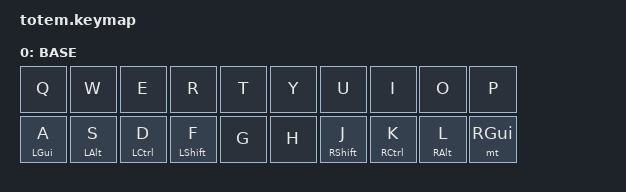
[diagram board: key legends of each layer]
//
//                                                        ▀▀▀▀▀     ▀▀▀▀▀          ▀▀█▀▀
//                                                        ▄▀▀▀▄  ▄  ▄▀▀▀▄  ▄  ▄▀▀▀▄  █  ▄▀▀▀▄
//                                                        █   █  █  █   █  █  █   █  █  █   █
//                                                         ▀▀▀   █   ▀▀▀   █   ▀▀▀   ▀   ▀▀▀
//                                                               █      ▄▄▄█▄▄▄    █   █  
//                                                               ▀      █  █  █     █▄█
//                                                             ▀▀▀▀▀    █  █  █      ▀
//                                                                      ▀  ▀  ▀
//
// ▄▄▄▄▄▄▄▄▄▄▄▄▄▄▄▄▄▄▄▄▄▄▄▄▄▄▄▄▄▄▄▄▄▄▄▄▄▄▄▄▄▄▄▄▄▄▄▄▄▄▄▄▄▄▄▄▄▄▄▄▄▄▄▄▄▄▄▄▄▄▄▄▄▄▄▄▄▄▄▄▄▄▄▄▄▄▄▄▄▄▄▄▄▄▄▄▄▄▄▄▄▄▄▄▄▄▄▄▄▄▄▄▄▄▄▄▄▄▄▄▄▄▄▄▄▄▄▄▄▄▄▄▄▄▄▄▄▄▄▄▄▄▄▄▄▄▄▄▄
       

#include <behaviors.dtsi>
#include <dt-bindings/zmk/keys.h>
#include <dt-bindings/zmk/bt.h>
#include <dt-bindings/zmk/outputs.h>

#define BASE 0

&mt {
  quick-tap-ms = <100>;
  global-quick-tap;
  flavor = "tap-preferred";
  tapping-term-ms = <170>;
};

/ {
     combos {
            compatible = "zmk,combos";
            combo_esc {
                timeout-ms = <50>;
                key-positions = <0 1>;
                bindings = <&kp ESC>;
            };
            combo_tvp {
                timeout-ms = <100>;
                key-positions = <11 12 13>;
                bindings = <&tog TVP1>;
            };
    };

    macros {
        gif: gif {
            label = "giphy";
            compatible = "zmk,behavior-macro";
            #binding-cells = <0>;
            bindings
                = <&macro_press &kp LSHFT>
                , <&macro_tap &kp N2>
                , <&macro_release &kp LSHFT>
                , <&macro_tap &kp G &kp I &kp F>
                ;
        };
    };

        keymap {
                compatible = "zmk,keymap";
// ▄▄▄▄▄▄▄▄▄▄▄▄▄▄▄▄▄▄▄▄▄▄▄▄▄▄▄▄▄▄▄▄▄▄▄▄▄▄▄▄▄▄▄▄▄▄▄▄▄▄▄▄▄▄▄▄▄▄▄▄▄▄▄▄▄▄▄▄▄▄▄▄▄▄▄▄▄▄▄▄▄▄▄▄▄▄▄▄▄▄▄▄▄▄▄▄▄▄▄▄▄▄▄▄▄▄▄▄▄▄▄▄▄▄▄▄▄▄▄▄▄▄▄▄▄▄▄▄▄▄▄▄▄▄▄▄▄▄▄▄▄▄▄▄▄▄▄▄▄

                base_layer {
// ┏━━━━━━━━━━━━━━━━━━━━━━━━━━━━━━━━━━━━━━━┓
label= "BASE"                              ;
// ┗━━━━━━━━━━━━━━━━━━━━━━━━━━━━━━━━━━━━━━━┛
//             ┏━━━━━━━━━━━┳━━━━━━━━━━━┳━━━━━━━━━━━┳━━━━━━━━━━━┳━━━━━━━━━━━┓   ┏━━━━━━━━━━━┳━━━━━━━━━━━┳━━━━━━━━━━━┳━━━━━━━━━━━┳━━━━━━━━━━━┓
//             ┃     Q     ┃     W     ┃     E     ┃     R     ┃     T     ┃   ┃     Y     ┃     U     ┃     I     ┃     O     ┃     P     ┃
//             ┣━━━━━━━━━━━╋━━━━━━━━━━━╋━━━━━━━━━━━╋━━━━━━━━━━━╋━━━━━━━━━━━┫   ┣━━━━━━━━━━━╋━━━━━━━━━━━╋━━━━━━━━━━━╋━━━━━━━━━━━╋━━━━━━━━━━━┫
//             ┃     A     ┃     S     ┃     D     ┃     F     ┃     G     ┃   ┃     H     ┃     J     ┃     K     ┃     L     ┃     ;     ┃
// ┏━━━━━━━━━━━╋━━━━━━━━━━━╋━━━━━━━━━━━╋━━━━━━━━━━━╋━━━━━━━━━━━╋━━━━━━━━━━━┫   ┣━━━━━━━━━━━╋━━━━━━━━━━━╋━━━━━━━━━━━╋━━━━━━━━━━━╋━━━━━━━━━━━╋━━━━━━━━━━━┓
// ┃    HYP    ┃     Z     ┃     X     ┃     C     ┃     V     ┃     B     ┃   ┃     N     ┃     M     ┃     ,     ┃     .     ┃     /     ┃           ┃
// ┗━━━━━━━━━━━┻━━━━━━━━━━━┻━━━━━━━━━━━╋━━━━━━━━━━━╋━━━━━━━━━━━╋━━━━━━━━━━━┫   ┣━━━━━━━━━━━╋━━━━━━━━━━━╋━━━━━━━━━━━╋━━━━━━━━━━━┻━━━━━━━━━━━┻━━━━━━━━━━━┛
//                                     ┃           ┃    TAB    ┃   BKSPC   ┃   ┃   SPACE   ┃    RET    ┃           ┃
//                                     ┗━━━━━━━━━━━┻━━━━━━━━━━━┻━━━━━━━━━━━┛   ┗━━━━━━━━━━━┻━━━━━━━━━━━┻━━━━━━━━━━━┛
 bindings = <
// ╷           ╷           ╷           ╷           ╷           ╷           ╷   ╷           ╷           ╷           ╷           ╷           ╷           ╷

                &kp Q       &kp W       &kp E       &kp R       &kp T           &kp Y       &kp U       &kp I       &kp O       &kp P
                &mt LGUI A  &mt LALT S  &mt LCTRL D &mt LSHFT F &kp G           &kp H       &mt RSHFT J &mt RCTRL K &mt RALT L  &mt RGUI ;
    &kp HYPR    &kp Z       &kp X       &kp C       &kp V       &kp B           &kp N       &kp M       &kp COMMA   &kp DOT     &kp FSLH    &kp KC_NO
                                        &kp KC_NO   &kp TAB     &kp BSPC        &kp SPACE   &kp RET     &kp KC_NO
                        >;
                };

        };
};
